# COMPUTE_CLUSTER0_CFG_WRAP_0_ECC_AGGR register map
Vendor: Texas Instruments
Peripheral module from a debugger description file (folder J721S2).
Registers are 32-bit, access not given, reset 0x0 unless marked. A register's access mark holds for its fields unless they carry their own. Offsets are as the file gives them; lines under a group give offsets from that group; [hi:lo] are bit positions; {n}, {i} and the like mark numbered series; 'fields as' and 'values as' point back to an identical list; <NAME> marks a mode.

## COMPUTE_CLUSTER0_CFG_WRAP_0_ECC_AGGR
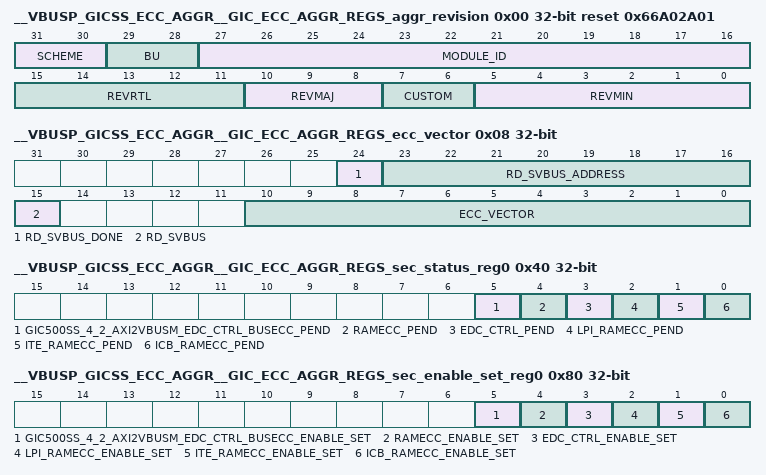
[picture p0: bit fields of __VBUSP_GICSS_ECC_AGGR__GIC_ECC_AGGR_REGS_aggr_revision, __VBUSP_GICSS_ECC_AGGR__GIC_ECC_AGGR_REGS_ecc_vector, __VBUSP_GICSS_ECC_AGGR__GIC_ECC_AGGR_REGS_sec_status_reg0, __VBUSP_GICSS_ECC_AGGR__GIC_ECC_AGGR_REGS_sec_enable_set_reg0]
0x00 __VBUSP_GICSS_ECC_AGGR__GIC_ECC_AGGR_REGS_aggr_revision ro reset 0x66A02A01 — Revision parameters
  [31:30] SCHEME
  [29:28] BU
  [27:16] MODULE_ID
  [15:11] REVRTL — RTL version
  [10:8] REVMAJ — Major version
  [7:6] CUSTOM — Custom version
  [5:0] REVMIN — Minor version
0x08 __VBUSP_GICSS_ECC_AGGR__GIC_ECC_AGGR_REGS_ecc_vector — ECC Vector Register
  [24] RD_SVBUS_DONE — Status to indicate if read on serial VBUS is complete, write of any value will clear this bit. (access R/W1TC)
  [23:16] RD_SVBUS_ADDRESS rw — Read address
  [15] RD_SVBUS — Write 1 to trigger a read on the serial VBUS (access R/W1TS)
  [10:0] ECC_VECTOR rw — Value written to select the corresponding ECC RAM for control or status
0x0C __VBUSP_GICSS_ECC_AGGR__GIC_ECC_AGGR_REGS_misc_status ro reset 0x6 — Misc Status
  [10:0] NUM_RAMS — Indicates the number of RAMS serviced by the ECC aggregator
0x10 __VBUSP_GICSS_ECC_AGGR__GIC_ECC_AGGR_REGS_reserved_svbus rw — Reference other documents that contain the ECC RAM wrapper and EDC controller serial vbus register sets.
  [31:0] DATA — Serial VBUS register data
0x3C __VBUSP_GICSS_ECC_AGGR__GIC_ECC_AGGR_REGS_sec_eoi_reg — EOI Register
  [0] EOI_WR — EOI Register (access R/W1TS)
0x40 __VBUSP_GICSS_ECC_AGGR__GIC_ECC_AGGR_REGS_sec_status_reg0 — Interrupt Status Register 0
  [5] GIC500SS_4_2_AXI2VBUSM_EDC_CTRL_BUSECC_PEND — Interrupt Pending Status for gic500ss_4_2_axi2vbusm_edc_ctrl_busecc_pend (access R/W1TS)
  [4] RAMECC_PEND — Interrupt Pending Status for ramecc_pend (access R/W1TS)
  [3] EDC_CTRL_PEND — Interrupt Pending Status for edc_ctrl_pend (access R/W1TS)
  [2] LPI_RAMECC_PEND — Interrupt Pending Status for lpi_ramecc_pend (access R/W1TS)
  [1] ITE_RAMECC_PEND — Interrupt Pending Status for ite_ramecc_pend (access R/W1TS)
  [0] ICB_RAMECC_PEND — Interrupt Pending Status for icb_ramecc_pend (access R/W1TS)
0x80 __VBUSP_GICSS_ECC_AGGR__GIC_ECC_AGGR_REGS_sec_enable_set_reg0 — Interrupt Enable Set Register 0
  [5] GIC500SS_4_2_AXI2VBUSM_EDC_CTRL_BUSECC_ENABLE_SET — Interrupt Enable Set Register for gic500ss_4_2_axi2vbusm_edc_ctrl_busecc_pend (access R/W1TS)
  [4] RAMECC_ENABLE_SET — Interrupt Enable Set Register for ramecc_pend (access R/W1TS)
  [3] EDC_CTRL_ENABLE_SET — Interrupt Enable Set Register for edc_ctrl_pend (access R/W1TS)
  [2] LPI_RAMECC_ENABLE_SET — Interrupt Enable Set Register for lpi_ramecc_pend (access R/W1TS)
  [1] ITE_RAMECC_ENABLE_SET — Interrupt Enable Set Register for ite_ramecc_pend (access R/W1TS)
  [0] ICB_RAMECC_ENABLE_SET — Interrupt Enable Set Register for icb_ramecc_pend (access R/W1TS)
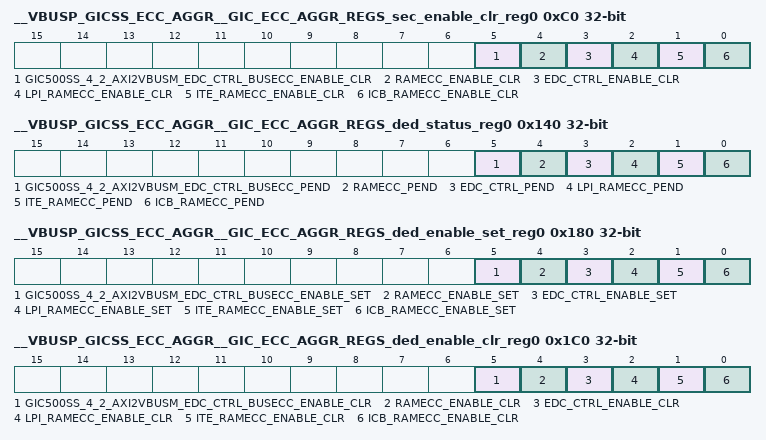
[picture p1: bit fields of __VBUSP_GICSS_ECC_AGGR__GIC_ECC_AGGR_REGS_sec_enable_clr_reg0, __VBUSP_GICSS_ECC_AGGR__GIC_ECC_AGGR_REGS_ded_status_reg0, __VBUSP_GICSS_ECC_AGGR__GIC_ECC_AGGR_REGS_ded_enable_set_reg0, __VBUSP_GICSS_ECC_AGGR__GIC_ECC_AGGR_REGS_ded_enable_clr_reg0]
0xC0 __VBUSP_GICSS_ECC_AGGR__GIC_ECC_AGGR_REGS_sec_enable_clr_reg0 — Interrupt Enable Clear Register 0
  [5] GIC500SS_4_2_AXI2VBUSM_EDC_CTRL_BUSECC_ENABLE_CLR — Interrupt Enable Clear Register for gic500ss_4_2_axi2vbusm_edc_ctrl_busecc_pend (access R/W1TC)
  [4] RAMECC_ENABLE_CLR — Interrupt Enable Clear Register for ramecc_pend (access R/W1TC)
  [3] EDC_CTRL_ENABLE_CLR — Interrupt Enable Clear Register for edc_ctrl_pend (access R/W1TC)
  [2] LPI_RAMECC_ENABLE_CLR — Interrupt Enable Clear Register for lpi_ramecc_pend (access R/W1TC)
  [1] ITE_RAMECC_ENABLE_CLR — Interrupt Enable Clear Register for ite_ramecc_pend (access R/W1TC)
  [0] ICB_RAMECC_ENABLE_CLR — Interrupt Enable Clear Register for icb_ramecc_pend (access R/W1TC)
0x13C __VBUSP_GICSS_ECC_AGGR__GIC_ECC_AGGR_REGS_ded_eoi_reg — EOI Register
  [0] EOI_WR — EOI Register (access R/W1TS)
0x140 __VBUSP_GICSS_ECC_AGGR__GIC_ECC_AGGR_REGS_ded_status_reg0 — Interrupt Status Register 0
  fields as __VBUSP_GICSS_ECC_AGGR__GIC_ECC_AGGR_REGS_sec_status_reg0
0x180 __VBUSP_GICSS_ECC_AGGR__GIC_ECC_AGGR_REGS_ded_enable_set_reg0 — Interrupt Enable Set Register 0
  fields as __VBUSP_GICSS_ECC_AGGR__GIC_ECC_AGGR_REGS_sec_enable_set_reg0
0x1C0 __VBUSP_GICSS_ECC_AGGR__GIC_ECC_AGGR_REGS_ded_enable_clr_reg0 — Interrupt Enable Clear Register 0
  fields as __VBUSP_GICSS_ECC_AGGR__GIC_ECC_AGGR_REGS_sec_enable_clr_reg0
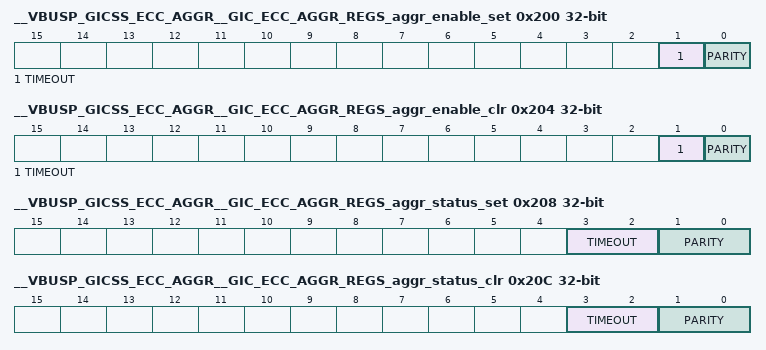
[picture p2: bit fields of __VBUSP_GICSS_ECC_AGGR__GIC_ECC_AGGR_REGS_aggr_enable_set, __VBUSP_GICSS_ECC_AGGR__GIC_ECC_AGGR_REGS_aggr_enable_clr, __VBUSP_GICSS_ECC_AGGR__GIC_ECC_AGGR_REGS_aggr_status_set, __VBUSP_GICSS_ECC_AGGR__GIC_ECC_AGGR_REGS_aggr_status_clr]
0x200 __VBUSP_GICSS_ECC_AGGR__GIC_ECC_AGGR_REGS_aggr_enable_set — AGGR interrupt enable set Register
  [1] TIMEOUT — interrupt enable set for svbus timeout errors (access R/W1TS)
  [0] PARITY — interrupt enable set for parity errors (access R/W1TS)
0x204 __VBUSP_GICSS_ECC_AGGR__GIC_ECC_AGGR_REGS_aggr_enable_clr — AGGR interrupt enable clear Register
  [1] TIMEOUT — interrupt enable clear for svbus timeout errors (access R/W1TC)
  [0] PARITY — interrupt enable clear for parity errors (access R/W1TC)
0x208 __VBUSP_GICSS_ECC_AGGR__GIC_ECC_AGGR_REGS_aggr_status_set — AGGR interrupt status set Register
  [3:2] TIMEOUT — interrupt status set for svbus timeout errors (access R/WI)
  [1:0] PARITY — interrupt status set for parity errors (access R/WI)
0x20C __VBUSP_GICSS_ECC_AGGR__GIC_ECC_AGGR_REGS_aggr_status_clr — AGGR interrupt status clear Register
  [3:2] TIMEOUT — interrupt status clear for svbus timeout errors (access R/WD)
  [1:0] PARITY — interrupt status clear for parity errors (access R/WD)
